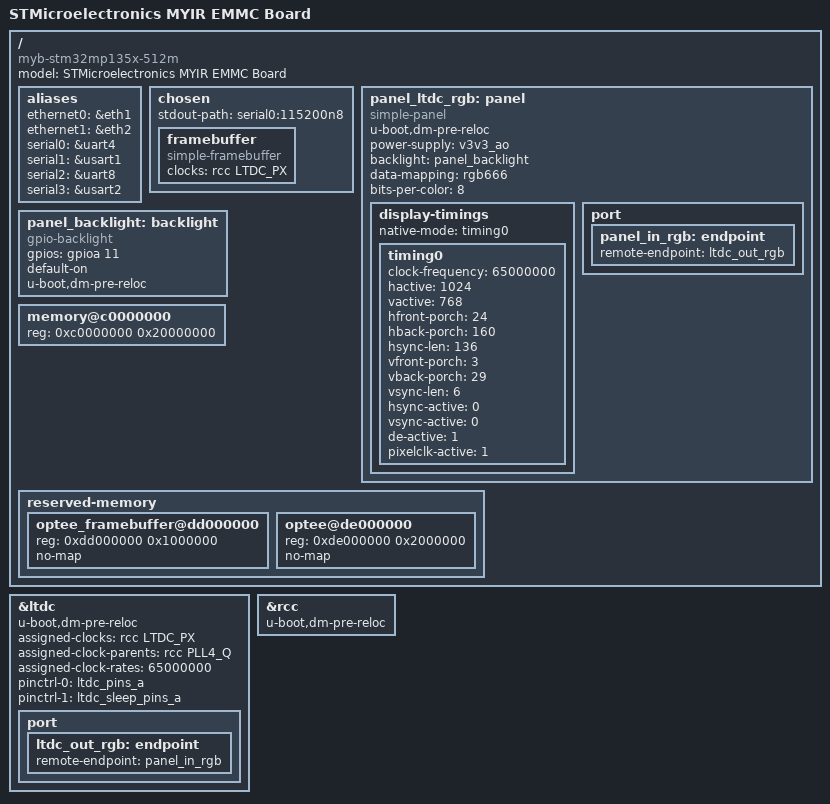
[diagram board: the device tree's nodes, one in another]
// SPDX-License-Identifier: (GPL-2.0+ OR BSD-3-Clause)
/*
 * Copyright (C) STMicroelectronics 2021 - All Rights Reserved
 * Author: Alexandre Torgue <alexandre.torgue@foss.st.com> for STMicroelectronics.
 */

#include "myb-stm32mp135x-base.dts"

/ {
	model = "STMicroelectronics MYIR EMMC  Board";
	compatible = "myb-stm32mp135x-512m", "st,stm32mp135";

	aliases {
		ethernet0 = &eth1;
		ethernet1 = &eth2;
		serial0 = &uart4;
		serial1 = &usart1;
		serial2 = &uart8;
		serial3 = &usart2;
	};

	chosen {
		#address-cells = <1>;
		#size-cells = <1>;
		ranges;
		stdout-path = "serial0:115200n8";

		framebuffer {
			compatible = "simple-framebuffer";
			clocks = <&rcc LTDC_PX>;
			status = "okay";
		};
	};

	/*LCD Panel*/
	panel_ltdc_rgb: panel {
		compatible = "simple-panel";
		status = "okay";
		u-boot,dm-pre-reloc;
		bootph-all;
		power-supply = <&v3v3_ao>;
		backlight = <&panel_backlight>;
		data-mapping = "rgb666";
		bits-per-color = <8>;
		display-timings {
			native-mode = <&timing0>;
			timing0: timing0 {
				clock-frequency = <65000000>;
				hactive = <1024>;
				vactive = <768>;
				hfront-porch = <24>;
				hback-porch  = <160>;
				hsync-len    = <136>;
				vfront-porch = <3>;
				vback-porch  = <29>;
				vsync-len    = <6>;
				hsync-active = <0>;
				vsync-active = <0>;
				de-active    = <1>;
				pixelclk-active = <1>;
			};
		};
		port {
			panel_in_rgb: endpoint {
				remote-endpoint = <&ltdc_out_rgb>;
			};
		};
	};

	panel_backlight: backlight {
		compatible = "gpio-backlight";
		gpios = <&gpioa 11 GPIO_ACTIVE_HIGH>;
		default-on;
		status = "okay";
		u-boot,dm-pre-reloc;
		bootph-all;
	};

	memory@c0000000 {
		device_type = "memory";
		reg = <0xc0000000 0x20000000>;
	};

	reserved-memory {
		#address-cells = <1>;
		#size-cells = <1>;
		ranges;

		optee_framebuffer@dd000000 {
			reg = <0xdd000000 0x1000000>;
			no-map;
		};

		optee@de000000 {
			reg = <0xde000000 0x2000000>;
			no-map;
		};
	};
};

&ltdc {
	status = "okay";
	u-boot,dm-pre-reloc;
	bootph-all;

	assigned-clocks = <&rcc LTDC_PX>;
	assigned-clock-parents = <&rcc PLL4_Q>;
	assigned-clock-rates = <65000000>;

	pinctrl-names = "default", "sleep";
	pinctrl-0 = <&ltdc_pins_a>;
	pinctrl-1 = <&ltdc_sleep_pins_a>;

	port {
		ltdc_out_rgb: endpoint {
			remote-endpoint = <&panel_in_rgb>;
		};
	};
};

/* 开启 RCC 对应的显示时钟 */
&rcc {
	status = "okay";
	u-boot,dm-pre-reloc;
	bootph-all;
};
